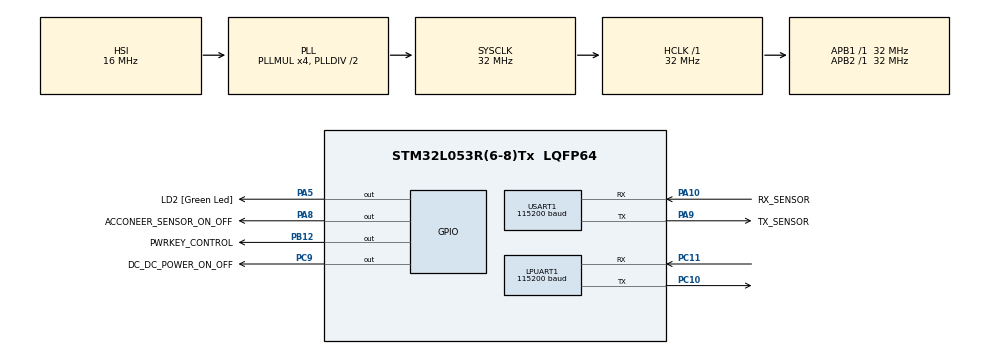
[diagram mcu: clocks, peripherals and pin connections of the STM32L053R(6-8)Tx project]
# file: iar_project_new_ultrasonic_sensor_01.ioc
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LPUART1.BaudRate=115200
LPUART1.WordLength=UART_WORDLENGTH_8B
Mcu.Family=STM32L0
Mcu.Name=STM32L053R(6-8)Tx
Mcu.Package=LQFP64
NVIC.RCC_CRS_IRQn=true\:0\:0\:false\:false\:true\:true\:false\:true
NVIC.USART1_IRQn=true\:0\:0\:false\:false\:true\:true\:true\:true
PA10.GPIO_Label=RX_SENSOR
PA10.Mode=Asynchronous
PA10.Signal=USART1_RX
PA13.GPIO_Label=TMS
PA13.Mode=Serial_Wire
PA13.Signal=SYS_SWDIO
PA14.GPIO_Label=TCK
PA14.Mode=Serial_Wire
PA14.Signal=SYS_SWCLK
PA5.GPIO_Label=LD2 [Green Led]
PA5.Signal=GPIO_Output
PA8.GPIO_Label=ACCONEER_SENSOR_ON_OFF
PA8.Signal=GPIO_Output
PA9.GPIO_Label=TX_SENSOR
PA9.Mode=Asynchronous
PA9.Signal=USART1_TX
PB12.GPIO_Label=PWRKEY_CONTROL
PB12.Signal=GPIO_Output
PC10.Mode=Asynchronous
PC10.Signal=LPUART1_TX
PC11.Mode=Asynchronous
PC11.Signal=LPUART1_RX
PC14-OSC32_IN.Mode=LSE-External-Oscillator
PC14-OSC32_IN.Signal=RCC_OSC32_IN
PC15-OSC32_OUT.Mode=LSE-External-Oscillator
PC15-OSC32_OUT.Signal=RCC_OSC32_OUT
PC9.GPIO_Label=DC_DC_POWER_ON_OFF
PC9.Signal=GPIO_Output
PH0-OSC_IN.Mode=HSE-External-Oscillator
PH0-OSC_IN.Signal=RCC_OSC_IN
PH1-OSC_OUT.Mode=HSE-External-Oscillator
PH1-OSC_OUT.Signal=RCC_OSC_OUT
ProjectManager.HeapSize=0x200
ProjectManager.StackSize=0x400
ProjectManager.TargetToolchain=EWARM V8.32
RCC.AHBFreq_Value=32000000
RCC.APB1Freq_Value=32000000
RCC.APB1TimFreq_Value=32000000
RCC.APB2Freq_Value=32000000
RCC.APB2TimFreq_Value=32000000
RCC.HCLKFreq_Value=32000000
RCC.HSE_VALUE=8000000
RCC.HSI16_VALUE=16000000
RCC.HSI48_VALUE=48000000
RCC.HSI_VALUE=16000000
RCC.MSI_VALUE=2097000
RCC.PLLMUL=RCC_PLLMUL_4
RCC.SYSCLKFreq_VALUE=32000000
RCC.SYSCLKSource=RCC_SYSCLKSOURCE_PLLCLK
RCC.VCOOutputFreq_Value=64000000
USART1.BaudRate=115200
USART1.VirtualMode-Asynchronous=VM_ASYNC
board=NUCLEO-L053R8

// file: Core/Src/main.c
/* USER CODE BEGIN Header */
/**
  ******************************************************************************
  * @file           : main.c
  * @brief          : Main program body
  ******************************************************************************
  * @attention
  *
  * Copyright (c) 2023 STMicroelectronics.
  * All rights reserved.
  *
  * This software is licensed under terms that can be found in the LICENSE file
  * in the root directory of this software component.
  * If no LICENSE file comes with this software, it is provided AS-IS.
  *
  ******************************************************************************
  */
/* USER CODE END Header */
#include "main.h"

/* USER CODE BEGIN Includes */
#include "usr_general.h"
/* USER CODE END Includes */

/* USER CODE BEGIN PV */
// #define UART_TOTAL_BYTES 512

// uint8_t globalRxBuffer[UART_TOTAL_BYTES];
// bool flag;
// uint8_t *ptr = globalRxBuffer;
/* USER CODE END PV */

void SystemClock_Config(void);

/* USER CODE BEGIN 0 */
// void USART_CONTROL(void)
// {
// 	if (__HAL_UART_GET_FLAG(&huart1, UART_FLAG_IDLE) &&  flag == false)
// 	{
// 		__HAL_UART_CLEAR_IDLEFLAG(&huart1);
// 		flag = true;
// 	}
// }

/* USER CODE END 0 */

/**
  * @retval int
  */
int main(void)
{

  /* MCU Configuration--------------------------------------------------------*/

  /* Reset of all peripherals, Initializes the Flash interface and the Systick. */
  HAL_Init();

  /* Configure the system clock */
  SystemClock_Config();

  /* Initialize all configured peripherals */
  MX_GPIO_Init();
  MX_LPUART1_UART_Init();
  MX_USART1_UART_Init();
  /* USER CODE BEGIN 2 */

  HAL_GPIO_WritePin(GPIOA, GPIO_PIN_8, GPIO_PIN_SET);
  HAL_GPIO_WritePin(GPIOC, GPIO_PIN_9, GPIO_PIN_SET);
  HAL_GPIO_WritePin(GPIOB, GPIO_PIN_12, GPIO_PIN_SET);

  // __HAL_UART_ENABLE_IT(&huart1, UART_IT_IDLE);

  UsrSystemInitial();

  /* USER CODE END 2 */

  /* Infinite loop */
  while (1)
  {

    /* USER CODE BEGIN 3 */
    UsrSystemGeneral();
    // if (flag)
    // {
    //   HAL_UART_Receive_IT(&huart1, globalRxBuffer, 512);
    //   HAL_UART_Transmit(&hlpuart1, globalRxBuffer, strlen(globalRxBuffer), 100);
    //   huart1.pRxBuffPtr = ptr;
    //   huart1.RxXferCount = 0;
    //   memset(globalRxBuffer, 0, 512);
    //   flag = false;
    // }

  }
  /* USER CODE END 3 */
}

void SystemClock_Config(void)
{
  RCC_OscInitTypeDef RCC_OscInitStruct = {0};
  RCC_ClkInitTypeDef RCC_ClkInitStruct = {0};
  RCC_PeriphCLKInitTypeDef PeriphClkInit = {0};

  /** Configure the main internal regulator output voltage
  */
  __HAL_PWR_VOLTAGESCALING_CONFIG(PWR_REGULATOR_VOLTAGE_SCALE1);

  /** Initializes the RCC Oscillators according to the specified parameters
  * in the RCC_OscInitTypeDef structure.
  */
  RCC_OscInitStruct.OscillatorType = RCC_OSCILLATORTYPE_HSI;
  RCC_OscInitStruct.HSIState = RCC_HSI_ON;
  RCC_OscInitStruct.HSICalibrationValue = RCC_HSICALIBRATION_DEFAULT;
  RCC_OscInitStruct.PLL.PLLState = RCC_PLL_ON;
  RCC_OscInitStruct.PLL.PLLSource = RCC_PLLSOURCE_HSI;
  RCC_OscInitStruct.PLL.PLLMUL = RCC_PLLMUL_4;
  RCC_OscInitStruct.PLL.PLLDIV = RCC_PLLDIV_2;
  if (HAL_RCC_OscConfig(&RCC_OscInitStruct) != HAL_OK)
  {
    Error_Handler();
  }

  /** Initializes the CPU, AHB and APB buses clocks
  */
  RCC_ClkInitStruct.ClockType = RCC_CLOCKTYPE_HCLK|RCC_CLOCKTYPE_SYSCLK
                              |RCC_CLOCKTYPE_PCLK1|RCC_CLOCKTYPE_PCLK2;
  RCC_ClkInitStruct.SYSCLKSource = RCC_SYSCLKSOURCE_PLLCLK;
  RCC_ClkInitStruct.AHBCLKDivider = RCC_SYSCLK_DIV1;
  RCC_ClkInitStruct.APB1CLKDivider = RCC_HCLK_DIV1;
  RCC_ClkInitStruct.APB2CLKDivider = RCC_HCLK_DIV1;

  if (HAL_RCC_ClockConfig(&RCC_ClkInitStruct, FLASH_LATENCY_1) != HAL_OK)
  {
    Error_Handler();
  }
  PeriphClkInit.PeriphClockSelection = RCC_PERIPHCLK_USART1|RCC_PERIPHCLK_LPUART1;
  PeriphClkInit.Usart1ClockSelection = RCC_USART1CLKSOURCE_PCLK2;
  PeriphClkInit.Lpuart1ClockSelection = RCC_LPUART1CLKSOURCE_PCLK1;
  if (HAL_RCCEx_PeriphCLKConfig(&PeriphClkInit) != HAL_OK)
  {
    Error_Handler();
  }
}

void Error_Handler(void)
{
  __disable_irq();
  while (1)
  {
  }
}
